# STM32F423 register map
File version: 1.2
CPU: CM4 r0p1, little endian, MPU, FPU, 4 interrupt priority bits
Registers are 32-bit, read-write, reset 0x0 unless marked. A register's access mark holds for its fields unless they carry their own. Offsets are from the block's base; [hi:lo] are bit positions; {n}, {i} and the like mark numbered series.

## CAN1 — Controller area network
Base 0x40006400
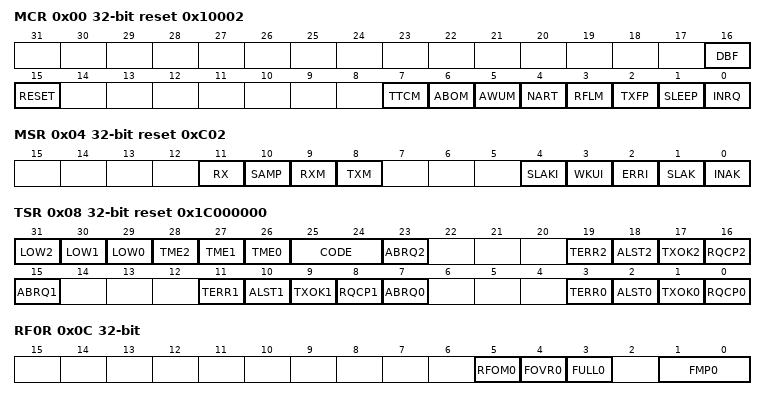
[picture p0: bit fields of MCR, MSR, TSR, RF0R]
0x00 MCR reset 0x10002 — master control register
  [16] DBF, [15] RESET, [7] TTCM, [6] ABOM, [5] AWUM, [4] NART, [3] RFLM, [2] TXFP, [1] SLEEP, [0] INRQ
0x04 MSR access per field reset 0xC02 — master status register
  [11] RX ro, [10] SAMP ro, [9] RXM ro, [8] TXM ro, [4] SLAKI rw, [3] WKUI rw, [2] ERRI rw, [1] SLAK ro, [0] INAK ro
0x08 TSR access per field reset 0x1C000000 — transmit status register
  [31] LOW2 ro — Lowest priority flag for mailbox 2
  [30] LOW1 ro — Lowest priority flag for mailbox 1
  [29] LOW0 ro — Lowest priority flag for mailbox 0
  [28] TME2 ro — Lowest priority flag for mailbox 2
  [27] TME1 ro — Lowest priority flag for mailbox 1
  [26] TME0 ro — Lowest priority flag for mailbox 0
  [25:24] CODE ro
  [23] ABRQ2 rw
  [19] TERR2 rw
  [18] ALST2 rw
  [17] TXOK2 rw
  [16] RQCP2 rw
  [15] ABRQ1 rw
  [11] TERR1 rw
  [10] ALST1 rw
  [9] TXOK1 rw
  [8] RQCP1 rw
  [7] ABRQ0 rw
  [3] TERR0 rw
  [2] ALST0 rw
  [1] TXOK0 rw
  [0] RQCP0 rw
0x0C RF0R access per field — receive FIFO 0 register
  [5] RFOM0 rw, [4] FOVR0 rw, [3] FULL0 rw, [1:0] FMP0 ro
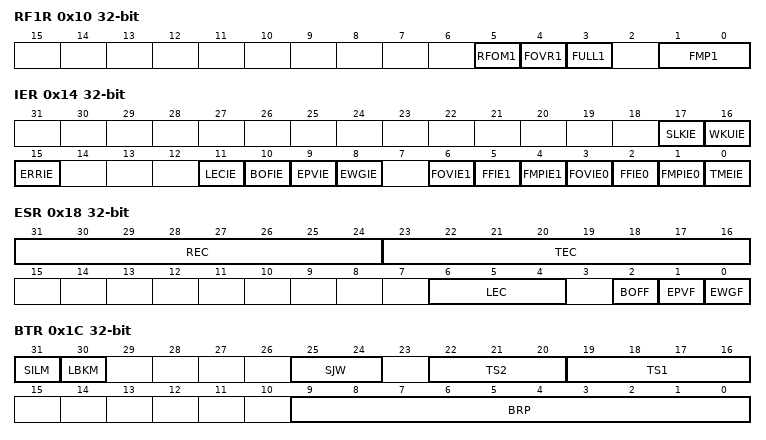
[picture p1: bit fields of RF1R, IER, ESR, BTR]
0x10 RF1R access per field — receive FIFO 1 register
  [5] RFOM1 rw, [4] FOVR1 rw, [3] FULL1 rw, [1:0] FMP1 ro
0x14 IER — interrupt enable register
  [17] SLKIE, [16] WKUIE, [15] ERRIE, [11] LECIE, [10] BOFIE, [9] EPVIE, [8] EWGIE, [6] FOVIE1, [5] FFIE1, [4] FMPIE1, [3] FOVIE0, [2] FFIE0, [1] FMPIE0, [0] TMEIE
0x18 ESR access per field — interrupt enable register
  [31:24] REC ro, [23:16] TEC ro, [6:4] LEC rw, [2] BOFF ro, [1] EPVF ro, [0] EWGF ro
0x1C BTR — bit timing register
  [31] SILM, [30] LBKM, [25:24] SJW, [22:20] TS2, [19:16] TS1, [9:0] BRP
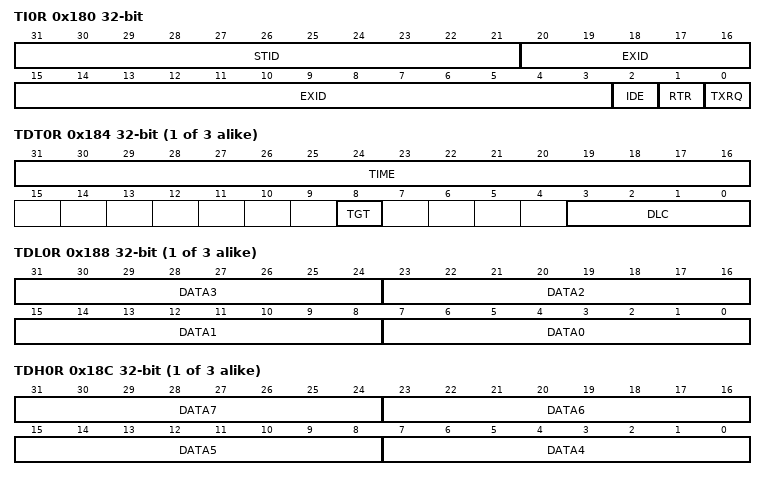
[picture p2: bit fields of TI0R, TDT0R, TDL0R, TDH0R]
0x180 TI0R — TX mailbox identifier register
  [31:21] STID, [20:3] EXID, [2] IDE, [1] RTR, [0] TXRQ
{0x184+0x10*i} TDT{i}R (i=0..2) — mailbox data length control and time stamp register
  [31:16] TIME, [8] TGT, [3:0] DLC
{0x188+0x10*i} TDL{i}R (i=0..2) — mailbox data low register
  [8n+7:8n] DATA{n} (n=0..3)
{0x18C+0x10*i} TDH{i}R (i=0..2) — mailbox data high register
  [8n-25:8n-32] DATA{n} (n=4..7)
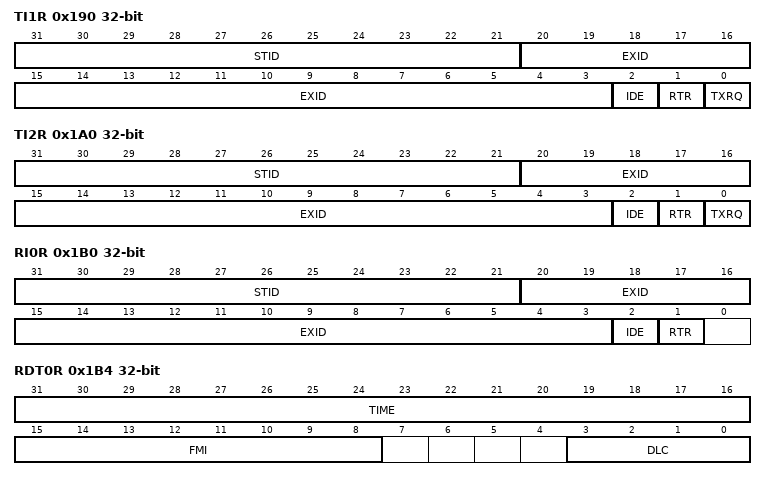
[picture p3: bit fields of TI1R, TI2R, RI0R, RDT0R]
0x190 TI1R — mailbox identifier register
  [31:21] STID, [20:3] EXID, [2] IDE, [1] RTR, [0] TXRQ
0x1A0 TI2R — mailbox identifier register
  [31:21] STID, [20:3] EXID, [2] IDE, [1] RTR, [0] TXRQ
0x1B0 RI0R ro — receive FIFO mailbox identifier register
  [31:21] STID, [20:3] EXID, [2] IDE, [1] RTR
0x1B4 RDT0R ro — mailbox data high register
  [31:16] TIME, [15:8] FMI, [3:0] DLC
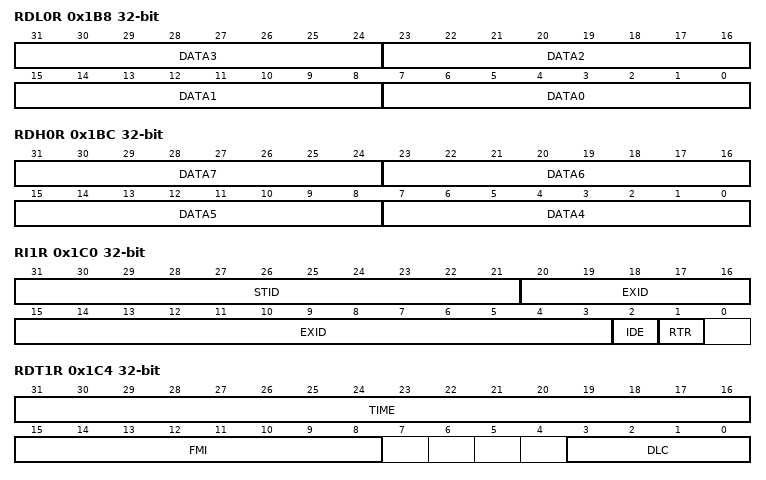
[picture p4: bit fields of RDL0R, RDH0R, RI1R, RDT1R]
0x1B8 RDL0R ro — mailbox data high register
  [8n+7:8n] DATA{n} (n=0..3)
0x1BC RDH0R ro — receive FIFO mailbox data high register
  [8n-25:8n-32] DATA{n} (n=4..7)
0x1C0 RI1R ro — mailbox data high register
  [31:21] STID, [20:3] EXID, [2] IDE, [1] RTR
0x1C4 RDT1R ro — mailbox data high register
  [31:16] TIME, [15:8] FMI, [3:0] DLC
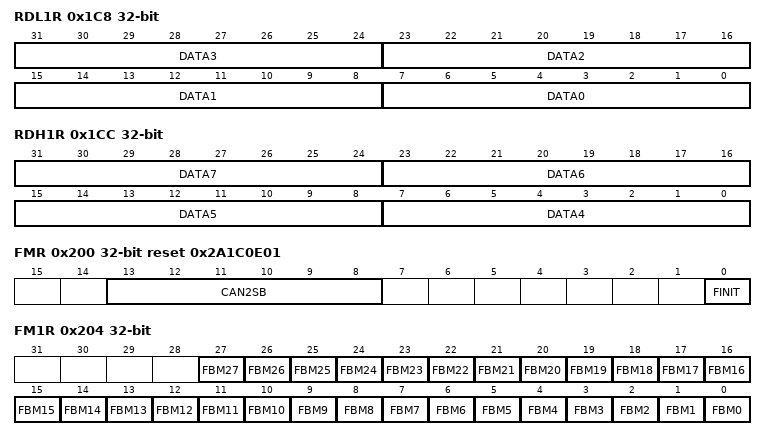
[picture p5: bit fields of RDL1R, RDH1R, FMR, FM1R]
0x1C8 RDL1R ro — mailbox data high register
  [8n+7:8n] DATA{n} (n=0..3)
0x1CC RDH1R ro — mailbox data high register
  [8n-25:8n-32] DATA{n} (n=4..7)
0x200 FMR reset 0x2A1C0E01 — filter master register
  [13:8] CAN2SB, [0] FINIT
0x204 FM1R — filter mode register
  [n] FBM{n} (n=0..27) — Filter mode
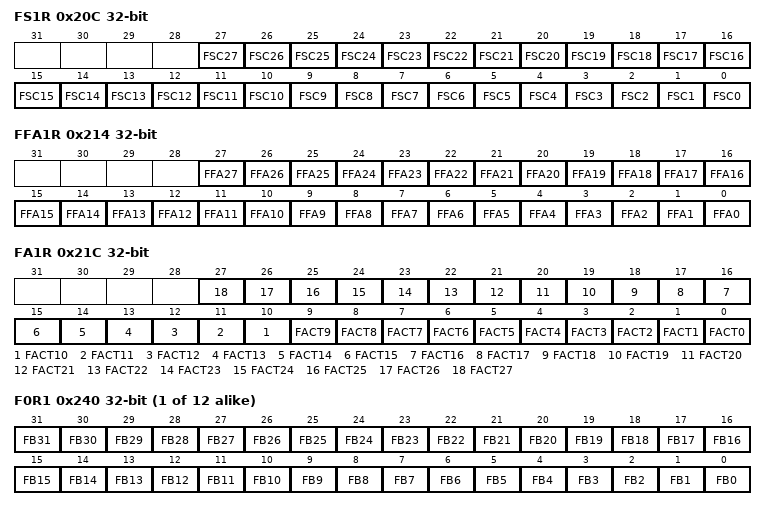
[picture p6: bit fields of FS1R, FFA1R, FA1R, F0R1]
0x20C FS1R — filter scale register
  [n] FSC{n} (n=0..27) — Filter scale configuration
0x214 FFA1R — filter FIFO assignment register
  [n] FFA{n} (n=0..27) — Filter FIFO assignment for filter {n}
0x21C FA1R — filter activation register
  [n] FACT{n} (n=0..27) — Filter active
{0x240+8i} F{i}R1 (i=0..11) — Filter bank {i} register 1
  [n] FB{n} (n=0..31) — Filter bits
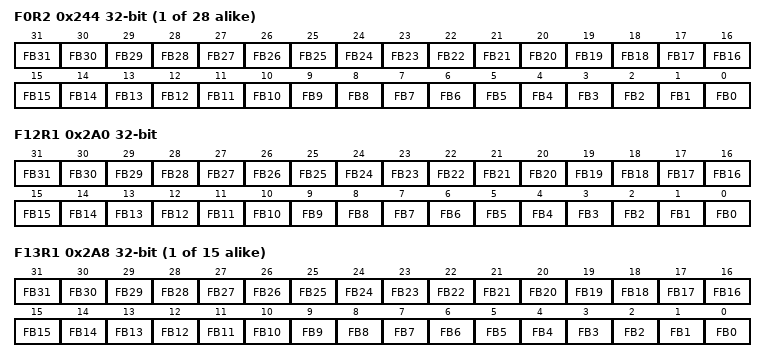
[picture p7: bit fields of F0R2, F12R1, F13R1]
{0x244+8i} F{i}R2 (i=0..27) — Filter bank {i} register 2
  [n] FB{n} (n=0..31) — Filter bits
0x2A0 F12R1 — Filter bank 4 register 1
  [n] FB{n} (n=0..31) — Filter bits
{0x240+8i} F{i}R1 (i=13..27) — Filter bank {i} register 1
  [n] FB{n} (n=0..31) — Filter bits

## CAN2 — CAN2; shared filter registers are accessed through CAN1
Base 0x40006800
Registers as CAN1, without FMR, FM1R, FS1R, FFA1R, FA1R, F{n}R1 (n=0..27), F{n}R2 (n=0..27).

## CAN3 — CAN3 with 14 independent filter banks
Base 0x40006C00
Registers as CAN1, without F{n}R1 (n=14..27), F{n}R2 (n=14..27); these are added or differ:
0x200 FMR reset 0x1 — filter master register
  [0] FINIT
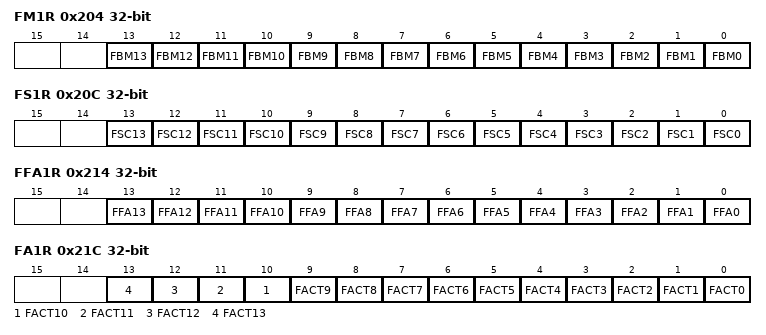
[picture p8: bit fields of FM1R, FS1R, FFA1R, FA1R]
0x204 FM1R — filter mode register
  [n] FBM{n} (n=0..13) — Filter mode
0x20C FS1R — filter scale register
  [n] FSC{n} (n=0..13) — Filter scale configuration
0x214 FFA1R — filter FIFO assignment register
  [n] FFA{n} (n=0..13) — Filter FIFO assignment for filter {n}
0x21C FA1R — filter activation register
  [n] FACT{n} (n=0..13) — Filter active
